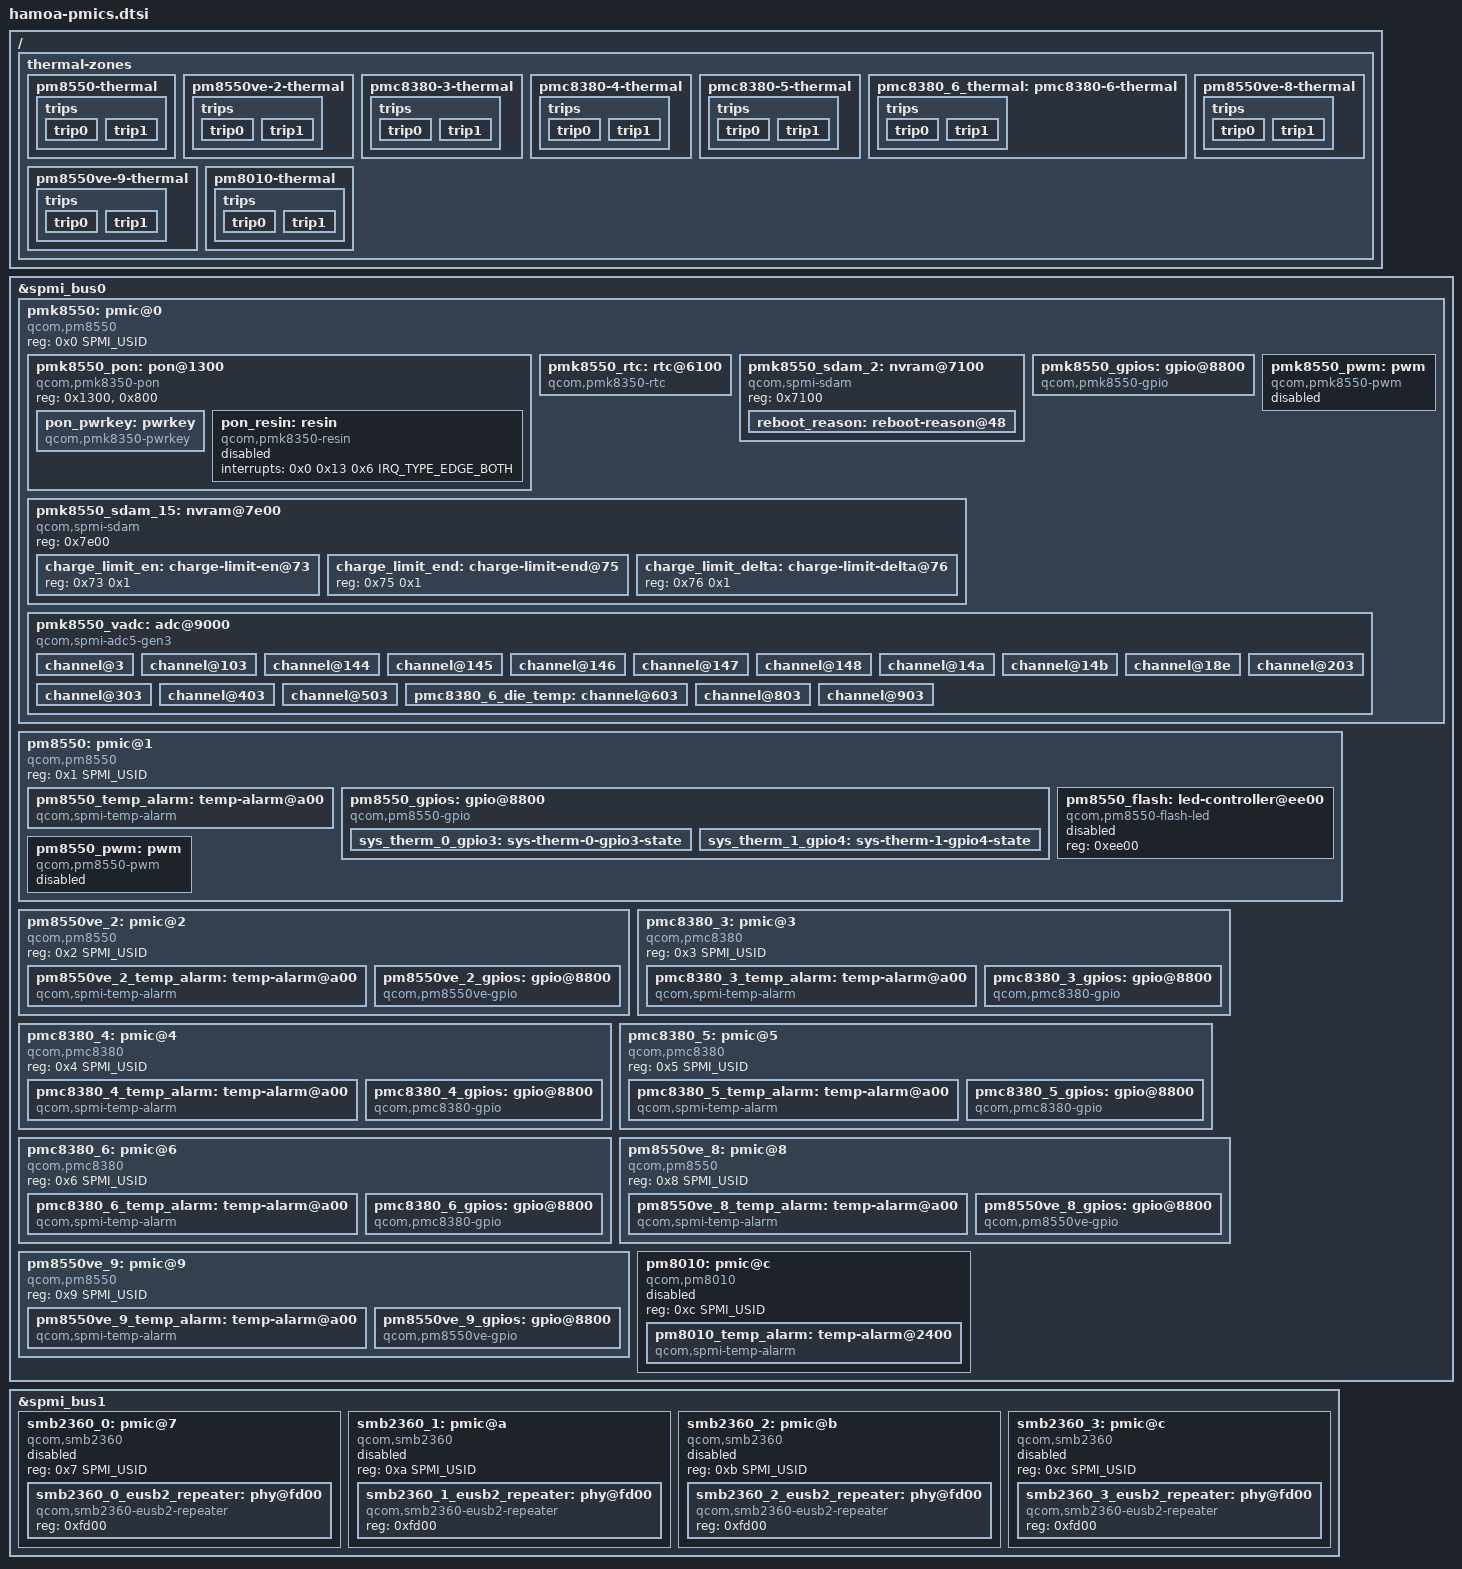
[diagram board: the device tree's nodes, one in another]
// SPDX-License-Identifier: BSD-3-Clause
/*
 * Copyright (c) 2024, Linaro Limited
 */

#include <dt-bindings/input/input.h>
#include <dt-bindings/input/linux-event-codes.h>
#include <dt-bindings/interrupt-controller/irq.h>
#include <dt-bindings/pinctrl/qcom,pmic-gpio.h>
#include <dt-bindings/spmi/spmi.h>
#include "qcom-adc5-gen3.h"

/ {
	thermal-zones {
		pm8550-thermal {
			polling-delay-passive = <100>;

			thermal-sensors = <&pm8550_temp_alarm>;

			trips {
				trip0 {
					temperature = <95000>;
					hysteresis = <0>;
					type = "passive";
				};

				trip1 {
					temperature = <115000>;
					hysteresis = <0>;
					type = "hot";
				};
			};
		};

		pm8550ve-2-thermal {
			polling-delay-passive = <100>;

			thermal-sensors = <&pm8550ve_2_temp_alarm>;

			trips {
				trip0 {
					temperature = <95000>;
					hysteresis = <0>;
					type = "passive";
				};

				trip1 {
					temperature = <115000>;
					hysteresis = <0>;
					type = "hot";
				};
			};
		};

		pmc8380-3-thermal {
			polling-delay-passive = <100>;

			thermal-sensors = <&pmc8380_3_temp_alarm>;

			trips {
				trip0 {
					temperature = <95000>;
					hysteresis = <0>;
					type = "passive";
				};

				trip1 {
					temperature = <115000>;
					hysteresis = <0>;
					type = "hot";
				};
			};
		};

		pmc8380-4-thermal {
			polling-delay-passive = <100>;

			thermal-sensors = <&pmc8380_4_temp_alarm>;

			trips {
				trip0 {
					temperature = <95000>;
					hysteresis = <0>;
					type = "passive";
				};

				trip1 {
					temperature = <115000>;
					hysteresis = <0>;
					type = "hot";
				};
			};
		};

		pmc8380-5-thermal {
			polling-delay-passive = <100>;

			thermal-sensors = <&pmc8380_5_temp_alarm>;

			trips {
				trip0 {
					temperature = <95000>;
					hysteresis = <0>;
					type = "passive";
				};

				trip1 {
					temperature = <115000>;
					hysteresis = <0>;
					type = "hot";
				};
			};
		};

		pmc8380_6_thermal: pmc8380-6-thermal {
			polling-delay-passive = <100>;

			thermal-sensors = <&pmc8380_6_temp_alarm>;

			trips {
				trip0 {
					temperature = <95000>;
					hysteresis = <0>;
					type = "passive";
				};

				trip1 {
					temperature = <115000>;
					hysteresis = <0>;
					type = "hot";
				};
			};
		};

		pm8550ve-8-thermal {
			polling-delay-passive = <100>;

			thermal-sensors = <&pm8550ve_8_temp_alarm>;

			trips {
				trip0 {
					temperature = <95000>;
					hysteresis = <0>;
					type = "passive";
				};

				trip1 {
					temperature = <115000>;
					hysteresis = <0>;
					type = "hot";
				};
			};
		};

		pm8550ve-9-thermal {
			polling-delay-passive = <100>;

			thermal-sensors = <&pm8550ve_9_temp_alarm>;

			trips {
				trip0 {
					temperature = <95000>;
					hysteresis = <0>;
					type = "passive";
				};

				trip1 {
					temperature = <115000>;
					hysteresis = <0>;
					type = "hot";
				};
			};
		};

		pm8010-thermal {
			polling-delay-passive = <100>;

			thermal-sensors = <&pm8010_temp_alarm>;

			trips {
				trip0 {
					temperature = <95000>;
					hysteresis = <0>;
					type = "passive";
				};

				trip1 {
					temperature = <115000>;
					hysteresis = <0>;
					type = "hot";
				};
			};
		};
	};
};

&spmi_bus0 {
	/* PMK8380 */
	pmk8550: pmic@0 {
		compatible = "qcom,pm8550", "qcom,spmi-pmic";
		reg = <0x0 SPMI_USID>;
		#address-cells = <1>;
		#size-cells = <0>;

		pmk8550_pon: pon@1300 {
			compatible = "qcom,pmk8350-pon";
			reg = <0x1300>, <0x800>;
			reg-names = "hlos", "pbs";

			pon_pwrkey: pwrkey {
				compatible = "qcom,pmk8350-pwrkey";
				interrupts = <0x0 0x13 0x7 IRQ_TYPE_EDGE_BOTH>;
				linux,code = <KEY_POWER>;
			};

			pon_resin: resin {
				compatible = "qcom,pmk8350-resin";
				interrupts = <0x0 0x13 0x6 IRQ_TYPE_EDGE_BOTH>;
				status = "disabled";
			};
		};

		pmk8550_rtc: rtc@6100 {
			compatible = "qcom,pmk8350-rtc";
			reg = <0x6100>, <0x6200>;
			reg-names = "rtc", "alarm";
			interrupts = <0x0 0x62 0x1 IRQ_TYPE_EDGE_RISING>;
			qcom,no-alarm; /* alarm owned by ADSP */
			qcom,uefi-rtc-info;
		};

		pmk8550_sdam_2: nvram@7100 {
			compatible = "qcom,spmi-sdam";
			reg = <0x7100>;
			#address-cells = <1>;
			#size-cells = <1>;
			ranges = <0 0x7100 0x100>;

			reboot_reason: reboot-reason@48 {
				reg = <0x48 0x1>;
				bits = <1 7>;
			};
		};

		pmk8550_sdam_15: nvram@7e00 {
			compatible = "qcom,spmi-sdam";
			reg = <0x7e00>;
			#address-cells = <1>;
			#size-cells = <1>;
			ranges = <0 0x7e00 0x100>;

			charge_limit_en: charge-limit-en@73 {
				reg = <0x73 0x1>;
			};

			charge_limit_end: charge-limit-end@75 {
				reg = <0x75 0x1>;
			};

			charge_limit_delta: charge-limit-delta@76 {
				reg = <0x76 0x1>;
			};
		};

		pmk8550_gpios: gpio@8800 {
			compatible = "qcom,pmk8550-gpio", "qcom,spmi-gpio";
			reg = <0xb800>;
			gpio-controller;
			gpio-ranges = <&pmk8550_gpios 0 0 6>;
			#gpio-cells = <2>;
			interrupt-controller;
			#interrupt-cells = <2>;
		};

		pmk8550_pwm: pwm {
			compatible = "qcom,pmk8550-pwm";

			#pwm-cells = <2>;

			status = "disabled";
		};

		pmk8550_vadc: adc@9000 {
			compatible = "qcom,spmi-adc5-gen3";
			reg = <0x9000>, <0x9100>;
			interrupts-extended = <&spmi_bus0 0x0 0x90 0x1 IRQ_TYPE_EDGE_RISING>,
					      <&spmi_bus0 0x0 0x91 0x1 IRQ_TYPE_EDGE_RISING>;
			#address-cells = <1>;
			#size-cells = <0>;
			#io-channel-cells = <1>;
			pinctrl-0 = <&sys_therm_0_gpio3>, <&sys_therm_1_gpio4>;
			pinctrl-names = "default";

			channel@3 {
				reg = <ADC5_GEN3_DIE_TEMP(0)>;
				label = "pmk8550_die_temp";
				qcom,pre-scaling = <1 1>;
			};

			channel@103 {
				reg = <ADC5_GEN3_DIE_TEMP(1)>;
				label = "pm8550_die_temp";
				qcom,pre-scaling = <1 1>;
			};

			channel@144 {
				reg = <ADC5_GEN3_AMUX1_THM_100K_PU(1)>;
				label = "pm8550_therm_2";
				qcom,ratiometric;
				qcom,hw-settle-time = <200>;
				qcom,pre-scaling = <1 1>;
			};

			channel@145 {
				reg = <ADC5_GEN3_AMUX2_THM_100K_PU(1)>;
				label = "pm8550_therm_3";
				qcom,ratiometric;
				qcom,hw-settle-time = <200>;
				qcom,pre-scaling = <1 1>;
			};

			channel@146 {
				reg = <ADC5_GEN3_AMUX3_THM_100K_PU(1)>;
				label = "pm8550_therm_4";
				qcom,ratiometric;
				qcom,hw-settle-time = <200>;
				qcom,pre-scaling = <1 1>;
			};

			channel@147 {
				reg = <ADC5_GEN3_AMUX4_THM_100K_PU(1)>;
				label = "pm8550_therm_5";
				qcom,ratiometric;
				qcom,hw-settle-time = <200>;
				qcom,pre-scaling = <1 1>;
			};

			channel@148 {
				reg = <ADC5_GEN3_AMUX5_THM_100K_PU(1)>;
				label = "pm8550_therm_6";
				qcom,ratiometric;
				qcom,hw-settle-time = <200>;
				qcom,pre-scaling = <1 1>;
			};

			channel@14a {
				reg = <ADC5_GEN3_AMUX1_GPIO_100K_PU(1)>;
				label = "pm8550_gpio_01";
				qcom,ratiometric;
				qcom,hw-settle-time = <200>;
				qcom,pre-scaling = <1 1>;
			};

			channel@14b {
				reg = <ADC5_GEN3_AMUX2_GPIO_100K_PU(1)>;
				label = "pm8550_gpio_02";
				qcom,ratiometric;
				qcom,hw-settle-time = <200>;
				qcom,pre-scaling = <1 1>;
			};

			channel@18e {
				reg = <ADC5_GEN3_VPH_PWR(1)>;
				label = "pm8550_vph_pwr";
				qcom,pre-scaling = <1 3>;
			};

			channel@203 {
				reg = <ADC5_GEN3_DIE_TEMP(2)>;
				label = "pm8550ve_2_die_temp";
				qcom,pre-scaling = <1 1>;
			};

			channel@303 {
				reg = <ADC5_GEN3_DIE_TEMP(3)>;
				label = "pmc8380_3_die_temp";
				qcom,pre-scaling = <1 1>;
			};

			channel@403 {
				reg = <ADC5_GEN3_DIE_TEMP(4)>;
				label = "pmc8380_4_die_temp";
				qcom,pre-scaling = <1 1>;
			};

			channel@503 {
				reg = <ADC5_GEN3_DIE_TEMP(5)>;
				label = "pmc8380_5_die_temp";
				qcom,pre-scaling = <1 1>;
			};

			pmc8380_6_die_temp: channel@603 {
				reg = <ADC5_GEN3_DIE_TEMP(6)>;
				label = "pmc8380_6_die_temp";
				qcom,pre-scaling = <1 1>;
			};

			channel@803 {
				reg = <ADC5_GEN3_DIE_TEMP(8)>;
				label = "pm8550ve_8_die_temp";
				qcom,pre-scaling = <1 1>;
			};

			channel@903 {
				reg = <ADC5_GEN3_DIE_TEMP(9)>;
				label = "pm8550ve_9_die_temp";
				qcom,pre-scaling = <1 1>;
			};
		};
	};

	/* PMC8380C */
	pm8550: pmic@1 {
		compatible = "qcom,pm8550", "qcom,spmi-pmic";
		reg = <0x1 SPMI_USID>;
		#address-cells = <1>;
		#size-cells = <0>;

		pm8550_temp_alarm: temp-alarm@a00 {
			compatible = "qcom,spmi-temp-alarm";
			reg = <0xa00>;
			interrupts = <0x1 0xa 0x0 IRQ_TYPE_EDGE_BOTH>;
			#thermal-sensor-cells = <0>;
			io-channels = <&pmk8550_vadc ADC5_GEN3_DIE_TEMP(1)>;
			io-channel-names = "thermal";
		};

		pm8550_gpios: gpio@8800 {
			compatible = "qcom,pm8550-gpio", "qcom,spmi-gpio";
			reg = <0x8800>;
			gpio-controller;
			gpio-ranges = <&pm8550_gpios 0 0 12>;
			#gpio-cells = <2>;
			interrupt-controller;
			#interrupt-cells = <2>;

			sys_therm_0_gpio3: sys-therm-0-gpio3-state {
				pins = "gpio3";
				function = PMIC_GPIO_FUNC_NORMAL;
				bias-high-impedance;
			};

			sys_therm_1_gpio4: sys-therm-1-gpio4-state {
				pins = "gpio4";
				function = PMIC_GPIO_FUNC_NORMAL;
				bias-high-impedance;
			};
		};

		pm8550_flash: led-controller@ee00 {
			compatible = "qcom,pm8550-flash-led", "qcom,spmi-flash-led";
			reg = <0xee00>;
			status = "disabled";
		};

		pm8550_pwm: pwm {
			compatible = "qcom,pm8550-pwm", "qcom,pm8350c-pwm";
			#pwm-cells = <2>;

			status = "disabled";
		};
	};

	/* PMC8380VE */
	pm8550ve_2: pmic@2 {
		compatible = "qcom,pm8550", "qcom,spmi-pmic";
		reg = <0x2 SPMI_USID>;
		#address-cells = <1>;
		#size-cells = <0>;

		pm8550ve_2_temp_alarm: temp-alarm@a00 {
			compatible = "qcom,spmi-temp-alarm";
			reg = <0xa00>;
			interrupts = <0x2 0xa 0x0 IRQ_TYPE_EDGE_BOTH>;
			#thermal-sensor-cells = <0>;
			io-channels = <&pmk8550_vadc ADC5_GEN3_DIE_TEMP(2)>;
			io-channel-names = "thermal";
		};

		pm8550ve_2_gpios: gpio@8800 {
			compatible = "qcom,pm8550ve-gpio", "qcom,spmi-gpio";
			reg = <0x8800>;
			gpio-controller;
			gpio-ranges = <&pm8550ve_2_gpios 0 0 8>;
			#gpio-cells = <2>;
			interrupt-controller;
			#interrupt-cells = <2>;
		};
	};

	/* PMC8380 is actually not a PM8550 series rebrand */
	pmc8380_3: pmic@3 {
		compatible = "qcom,pmc8380", "qcom,spmi-pmic";
		reg = <0x3 SPMI_USID>;
		#address-cells = <1>;
		#size-cells = <0>;

		pmc8380_3_temp_alarm: temp-alarm@a00 {
			compatible = "qcom,spmi-temp-alarm";
			reg = <0xa00>;
			interrupts = <0x3 0xa 0x0 IRQ_TYPE_EDGE_BOTH>;
			#thermal-sensor-cells = <0>;
			io-channels = <&pmk8550_vadc ADC5_GEN3_DIE_TEMP(3)>;
			io-channel-names = "thermal";
		};

		pmc8380_3_gpios: gpio@8800 {
			compatible = "qcom,pmc8380-gpio", "qcom,spmi-gpio";
			reg = <0x8800>;
			gpio-controller;
			gpio-ranges = <&pmc8380_3_gpios 0 0 10>;
			#gpio-cells = <2>;
			interrupt-controller;
			#interrupt-cells = <2>;
		};
	};

	pmc8380_4: pmic@4 {
		compatible = "qcom,pmc8380", "qcom,spmi-pmic";
		reg = <0x4 SPMI_USID>;
		#address-cells = <1>;
		#size-cells = <0>;

		pmc8380_4_temp_alarm: temp-alarm@a00 {
			compatible = "qcom,spmi-temp-alarm";
			reg = <0xa00>;
			interrupts = <0x4 0xa 0x0 IRQ_TYPE_EDGE_BOTH>;
			#thermal-sensor-cells = <0>;
			io-channels = <&pmk8550_vadc ADC5_GEN3_DIE_TEMP(4)>;
			io-channel-names = "thermal";
		};

		pmc8380_4_gpios: gpio@8800 {
			compatible = "qcom,pmc8380-gpio", "qcom,spmi-gpio";
			reg = <0x8800>;
			gpio-controller;
			gpio-ranges = <&pmc8380_4_gpios 0 0 10>;
			#gpio-cells = <2>;
			interrupt-controller;
			#interrupt-cells = <2>;
		};
	};

	pmc8380_5: pmic@5 {
		compatible = "qcom,pmc8380", "qcom,spmi-pmic";
		reg = <0x5 SPMI_USID>;
		#address-cells = <1>;
		#size-cells = <0>;

		pmc8380_5_temp_alarm: temp-alarm@a00 {
			compatible = "qcom,spmi-temp-alarm";
			reg = <0xa00>;
			interrupts = <0x5 0xa 0x0 IRQ_TYPE_EDGE_BOTH>;
			#thermal-sensor-cells = <0>;
			io-channels = <&pmk8550_vadc ADC5_GEN3_DIE_TEMP(5)>;
			io-channel-names = "thermal";
		};

		pmc8380_5_gpios: gpio@8800 {
			compatible = "qcom,pmc8380-gpio", "qcom,spmi-gpio";
			reg = <0x8800>;
			gpio-controller;
			gpio-ranges = <&pmc8380_5_gpios 0 0 10>;
			#gpio-cells = <2>;
			interrupt-controller;
			#interrupt-cells = <2>;
		};
	};

	pmc8380_6: pmic@6 {
		compatible = "qcom,pmc8380", "qcom,spmi-pmic";
		reg = <0x6 SPMI_USID>;
		#address-cells = <1>;
		#size-cells = <0>;

		pmc8380_6_temp_alarm: temp-alarm@a00 {
			compatible = "qcom,spmi-temp-alarm";
			reg = <0xa00>;
			interrupts = <0x6 0xa 0x0 IRQ_TYPE_EDGE_BOTH>;
			#thermal-sensor-cells = <0>;
			io-channels = <&pmk8550_vadc ADC5_GEN3_DIE_TEMP(6)>;
			io-channel-names = "thermal";
		};

		pmc8380_6_gpios: gpio@8800 {
			compatible = "qcom,pmc8380-gpio", "qcom,spmi-gpio";
			reg = <0x8800>;
			gpio-controller;
			gpio-ranges = <&pmc8380_6_gpios 0 0 10>;
			#gpio-cells = <2>;
			interrupt-controller;
			#interrupt-cells = <2>;
		};
	};

	/* PMC8380VE */
	pm8550ve_8: pmic@8 {
		compatible = "qcom,pm8550", "qcom,spmi-pmic";
		reg = <0x8 SPMI_USID>;
		#address-cells = <1>;
		#size-cells = <0>;

		pm8550ve_8_temp_alarm: temp-alarm@a00 {
			compatible = "qcom,spmi-temp-alarm";
			reg = <0xa00>;
			interrupts = <0x8 0xa 0x0 IRQ_TYPE_EDGE_BOTH>;
			#thermal-sensor-cells = <0>;
			io-channels = <&pmk8550_vadc ADC5_GEN3_DIE_TEMP(8)>;
			io-channel-names = "thermal";
		};

		pm8550ve_8_gpios: gpio@8800 {
			compatible = "qcom,pm8550ve-gpio", "qcom,spmi-gpio";
			reg = <0x8800>;
			gpio-controller;
			gpio-ranges = <&pm8550ve_8_gpios 0 0 8>;
			#gpio-cells = <2>;
			interrupt-controller;
			#interrupt-cells = <2>;
		};
	};

	/* PMC8380VE */
	pm8550ve_9: pmic@9 {
		compatible = "qcom,pm8550", "qcom,spmi-pmic";
		reg = <0x9 SPMI_USID>;
		#address-cells = <1>;
		#size-cells = <0>;

		pm8550ve_9_temp_alarm: temp-alarm@a00 {
			compatible = "qcom,spmi-temp-alarm";
			reg = <0xa00>;
			interrupts = <0x9 0xa 0x0 IRQ_TYPE_EDGE_BOTH>;
			#thermal-sensor-cells = <0>;
			io-channels = <&pmk8550_vadc ADC5_GEN3_DIE_TEMP(9)>;
			io-channel-names = "thermal";
		};

		pm8550ve_9_gpios: gpio@8800 {
			compatible = "qcom,pm8550ve-gpio", "qcom,spmi-gpio";
			reg = <0x8800>;
			gpio-controller;
			gpio-ranges = <&pm8550ve_9_gpios 0 0 8>;
			#gpio-cells = <2>;
			interrupt-controller;
			#interrupt-cells = <2>;
		};
	};

	pm8010: pmic@c {
		compatible = "qcom,pm8010", "qcom,spmi-pmic";
		reg = <0xc SPMI_USID>;
		#address-cells = <1>;
		#size-cells = <0>;

		status = "disabled";

		pm8010_temp_alarm: temp-alarm@2400 {
			compatible = "qcom,spmi-temp-alarm";
			reg = <0x2400>;
			interrupts = <0xc 0x24 0x0 IRQ_TYPE_EDGE_BOTH>;
			#thermal-sensor-cells = <0>;
		};
	};
};

&spmi_bus1 {
	smb2360_0: pmic@7 {
		compatible = "qcom,smb2360", "qcom,spmi-pmic";
		reg = <0x7 SPMI_USID>;
		#address-cells = <1>;
		#size-cells = <0>;

		status = "disabled";

		smb2360_0_eusb2_repeater: phy@fd00 {
			compatible = "qcom,smb2360-eusb2-repeater";
			reg = <0xfd00>;
			#phy-cells = <0>;
		};
	};

	smb2360_1: pmic@a {
		compatible = "qcom,smb2360", "qcom,spmi-pmic";
		reg = <0xa SPMI_USID>;
		#address-cells = <1>;
		#size-cells = <0>;

		status = "disabled";

		smb2360_1_eusb2_repeater: phy@fd00 {
			compatible = "qcom,smb2360-eusb2-repeater";
			reg = <0xfd00>;
			#phy-cells = <0>;
		};
	};

	smb2360_2: pmic@b {
		compatible = "qcom,smb2360", "qcom,spmi-pmic";
		reg = <0xb SPMI_USID>;
		#address-cells = <1>;
		#size-cells = <0>;

		status = "disabled";

		smb2360_2_eusb2_repeater: phy@fd00 {
			compatible = "qcom,smb2360-eusb2-repeater";
			reg = <0xfd00>;
			#phy-cells = <0>;
		};
	};

	smb2360_3: pmic@c {
		compatible = "qcom,smb2360", "qcom,spmi-pmic";
		reg = <0xc SPMI_USID>;
		#address-cells = <1>;
		#size-cells = <0>;

		status = "disabled";

		smb2360_3_eusb2_repeater: phy@fd00 {
			compatible = "qcom,smb2360-eusb2-repeater";
			reg = <0xfd00>;
			#phy-cells = <0>;
		};
	};
};
